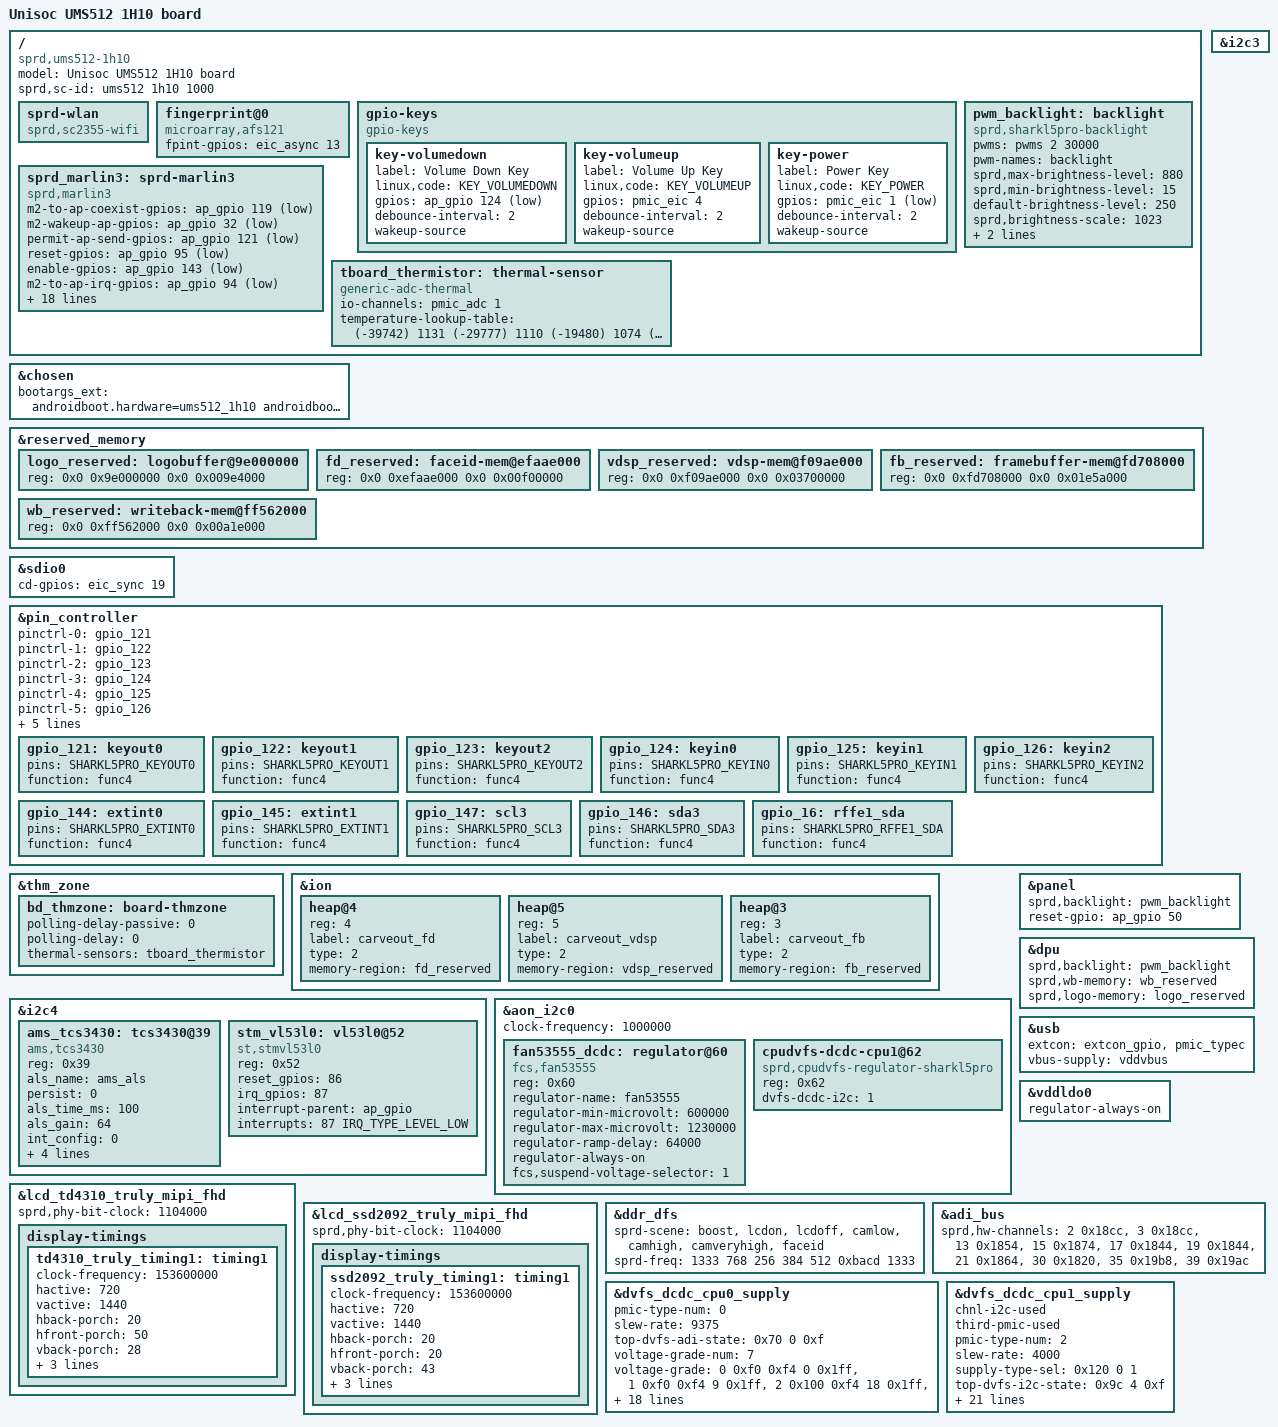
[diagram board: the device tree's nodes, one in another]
/dts-v1/;
/plugin/;

#include <dt-bindings/input/input.h>
#include <dt-bindings/gpio/gpio.h>
#include <dt-bindings/interrupt-controller/arm-gic.h>
#include <dt-bindings/clock/sprd,sharkl5pro-clk.h>
#include <dt-bindings/mfd/sprd,sc2730-regs.h>
#include <dt-bindings/mfd/sprd,sc2730-mask.h>
#include "../lcd/lcd_td4310_truly_mipi_fhd.dtsi"
#include "../lcd/lcd_ssd2092_truly_mipi_fhd.dtsi"
#include "../lcd/lcd_dummy_mipi.dtsi"

/ {

	model = "Unisoc UMS512 1H10 board";
	compatible = "sprd,ums512-1h10";
	sprd,sc-id = "ums512 1h10 1000";

	fragment {
		target-path = "/";
		__overlay__ {
			sprd-wlan {
				compatible = "sprd,sc2355-wifi";
			};

			fingerprint@0 {
				compatible = "microarray,afs121";
				fpint-gpios = <&eic_async 13 0>;
			};

			gpio-keys {
				compatible = "gpio-keys";

				key-volumedown {
					label = "Volume Down Key";
					linux,code = <KEY_VOLUMEDOWN>;
					gpios = <&ap_gpio 124 GPIO_ACTIVE_LOW>;
					debounce-interval = <2>;
					wakeup-source;
				};

				key-volumeup {
					label = "Volume Up Key";
					linux,code = <KEY_VOLUMEUP>;
					gpios = <&pmic_eic 4 GPIO_ACTIVE_HIGH>;
					debounce-interval = <2>;
					wakeup-source;
				};

				key-power {
					label = "Power Key";
					linux,code = <KEY_POWER>;
					gpios = <&pmic_eic 1 GPIO_ACTIVE_LOW>;
					debounce-interval = <2>;
					wakeup-source;
				};
			};

			pwm_backlight: backlight {
				compatible = "sprd,sharkl5pro-backlight";
				pwms = <&pwms 2 30000>;
				pwm-names = "backlight";
				sprd,max-brightness-level = <880>;
				sprd,min-brightness-level = <15>;
				default-brightness-level = <250>;
				sprd,brightness-scale = <1023>;
				brightness-levels = <
							  0   3   4   5   6   7
					  8   9  10  11  12  13  14  15  16  17
					 18  19  20  21  22  23  24  25  26  27
					 28  29  31  33  35  37  39  41  43  45
					 46  48  50  52  54  56  58  60  62  64
					 66  68  70  72  74  76  78  80  82  84
					 86  88  90  92  94  96  98 100 102 104
					106 108 110 112 114 116 118 120 122 124
					126 128 130 132 134 136 138 140 142 144
					146 148 150 152 154 156 158 160 162 164
					166 169 172 175 178 181 184 187 190 193
					196 199 202 205 208 211 214 217 220 223
					226 229 232 235 238 241 244 247 250 253
					256 259 262 265 268 271 274 277 280 283
					286 290 294 298 302 306 310 314 318 322
					326 330 334 338 342 346 350 354 358 362
					366 370 374 378 382 386 390 394 398 402
					406 410 414 418 422 426 430 434 438 442
					446 451 456 461 466 471 476 481 486 491
					496 501 506 511 516 521 526 531 536 541
					546 551 556 561 566 571 576 581 586 591
					596 601 606 611 616 621 626 631 636 641
					646 652 658 664 670 676 682 688 694 700
					706 712 718 724 730 736 742 748 754 760
					766 772 778 784 790 796 802 808 814 820
					826 832 838 844 850 856 862 868 874 880
				>;
			};

			sprd_marlin3: sprd-marlin3 {
				compatible = "sprd,marlin3";
				m2-to-ap-coexist-gpios = <&ap_gpio 119 GPIO_ACTIVE_LOW>;
				m2-wakeup-ap-gpios = <&ap_gpio 32 GPIO_ACTIVE_LOW>;
				permit-ap-send-gpios = <&ap_gpio 121 GPIO_ACTIVE_LOW>;
				reset-gpios = <&ap_gpio 95 GPIO_ACTIVE_LOW>;
				enable-gpios = <&ap_gpio 143 GPIO_ACTIVE_LOW>;
				m2-to-ap-irq-gpios = <&ap_gpio 94 GPIO_ACTIVE_LOW>;
				avdd12-supply = <&vddwcn>;
				avdd33-supply = <&vddwifipa>;
				dcxo18-supply = <&vddsim2>;

				clock-names = "clk_32k","source","enable";
				clocks = <&aon_clk CLK_AUX0>,
					 <&ext_32k>,
					 <&aonapb_gate CLK_AUX0_EB>;

				sdhci-name = <&sdio1>;
				sprd,btwf-file-name =
					"/dev/block/platform/soc/soc:ap-apb/71400000.sdio/by-name/wcnmodem";
				sprd,gnss-file-name =
					"/dev/block/platform/soc/soc:ap-apb/71400000.sdio/by-name/gnssmodem";
				adma-tx;
				adma-rx;
				/*
				 * bound parameter:
				 * [0]:addr offset, [1]:mask, [2]:unboundval, [3]:boundval
				 */
				avdd12-parent-bound-chip = <
					REG_ANA_SLP_DCDC_PD_CTRL
					MASK_ANA_SLP_DCDCGEN1_PD_EN 0x0 MASK_ANA_SLP_DCDCGEN1_PD_EN>;
				avdd12-bound-wbreq = <
					REG_ANA_LDO_XTL_EN10
					MASK_ANA_LDO_VDDWCN_EXT_XTL3_EN 0x0 MASK_ANA_LDO_VDDWCN_EXT_XTL3_EN>;
				avdd33-bound-wbreq = <
					REG_ANA_LDO_XTL_EN11
					MASK_ANA_LDO_VDDWIFIPA_EXT_XTL3_EN 0x0 MASK_ANA_LDO_VDDWIFIPA_EXT_XTL3_EN>;
			};

			tboard_thermistor:thermal-sensor {
				compatible = "generic-adc-thermal";
				#thermal-sensor-cells = <0>;
				io-channels = <&pmic_adc 1>;
				io-channel-names = "sensor-channel";
				temperature-lookup-table = <    (-39742) 1131
								(-29777) 1110
								(-19480) 1074
								(-4679) 983
								10110 838
								24805 654
								44922 413
								54903 316
								64895 238
								74884 178
								84883 133
								94883 100
								104880 75
								114889 57
								124872 43 >;
			};
		};
	};
};

&chosen {
	bootargs_ext = "androidboot.hardware=ums512_1h10 androidboot.dtbo_idx=0";
};

&reserved_memory {

	logo_reserved: logobuffer@9e000000{
		reg = <0x0 0x9e000000 0x0 0x009e4000>;
	};

	fd_reserved: faceid-mem@efaae000 {
		reg = <0x0 0xefaae000 0x0 0x00f00000>;
	};

	vdsp_reserved: vdsp-mem@f09ae000 {
		reg = <0x0 0xf09ae000 0x0 0x03700000>;
	};
/*
	gpu_reserved: gpu-mem@fb8ae000 {
		reg = <0x0 0xfb8ae000 0x0 0x01e5a000>;
	};
*/

	fb_reserved: framebuffer-mem@fd708000 {
		reg = <0x0 0xfd708000 0x0 0x01e5a000>;
	};

	wb_reserved: writeback-mem@ff562000 {
		reg = <0x0 0xff562000 0x0 0x00a1e000>;
	};

};

&sdio0 {
	cd-gpios = <&eic_sync 19 GPIO_ACTIVE_HIGH>;
};

&pin_controller {
	pinctrl-names =
	/* keyout0 ~ keyout2 */
	"gpio_121", "gpio_122", "gpio_123",
	/* keyin0 ~ keyin2 */
	"gpio_124", "gpio_125", "gpio_126",
	/* extint0, extint1, scl3, sda3, sda */
	"gpio_144", "gpio_145", "gpio_146", "gpio_147", "gpio_16";

	pinctrl-0 = <&gpio_121>;
	pinctrl-1 = <&gpio_122>;
	pinctrl-2 = <&gpio_123>;
	pinctrl-3 = <&gpio_124>;
	pinctrl-4 = <&gpio_125>;
	pinctrl-5 = <&gpio_126>;
	pinctrl-6 = <&gpio_144>;
	pinctrl-7 = <&gpio_145>;
	pinctrl-8 = <&gpio_146>;
	pinctrl-9 = <&gpio_147>;
	pinctrl-10 = <&gpio_16>;

	gpio_121: keyout0 {
		pins = "SHARKL5PRO_KEYOUT0";
		function = "func4";
	};

	gpio_122: keyout1 {
		pins = "SHARKL5PRO_KEYOUT1";
		function = "func4";
	};

	gpio_123: keyout2 {
		pins = "SHARKL5PRO_KEYOUT2";
		function = "func4";
	};

	gpio_124: keyin0 {
		pins = "SHARKL5PRO_KEYIN0";
		function = "func4";
	};

	gpio_125: keyin1 {
		pins = "SHARKL5PRO_KEYIN1";
		function = "func4";
	};

	gpio_126: keyin2 {
		pins = "SHARKL5PRO_KEYIN2";
		function = "func4";
	};

	gpio_144: extint0 {
		pins = "SHARKL5PRO_EXTINT0";
		function = "func4";
	};

	gpio_145: extint1 {
		pins = "SHARKL5PRO_EXTINT1";
		function = "func4";
	};

	gpio_147: scl3 {
		pins = "SHARKL5PRO_SCL3";
		function = "func4";
	};

	gpio_146: sda3 {
		pins = "SHARKL5PRO_SDA3";
		function = "func4";
	};

	gpio_16: rffe1_sda {
		pins = "SHARKL5PRO_RFFE1_SDA";
		function = "func4";
	};
};

&thm_zone {
	bd_thmzone: board-thmzone {
		polling-delay-passive = <0>;
		polling-delay = <0>;
		thermal-sensors = <&tboard_thermistor>;
	};
};

&ion {
	heap@4 {
		reg = <4>;
		label = "carveout_fd";
		type = <2>;
		memory-region = <&fd_reserved>;
	};

	heap@5 {
		reg = <5>;
		label = "carveout_vdsp";
		type = <2>;
		memory-region = <&vdsp_reserved>;
	};
};

&i2c3 {
	status = "okay";

};

&i2c4 {
	status = "okay";


	ams_tcs3430: tcs3430@39 {
		compatible = "ams,tcs3430";
		reg = <0x39>;
		als_name = "ams_als";
		persist = <0>;
		als_time_ms = <100>;
		als_gain = <64>;
		int_config = <0>;
		als_can_wake = <1>;
		irq_gpios = <112>;
		interrupt-parent = <&ap_gpio>;
		interrupts = <112 IRQ_TYPE_LEVEL_LOW>;
	};

	stm_vl53l0: vl53l0@52 {
		compatible = "st,stmvl53l0";
		reg = <0x52>;
		reset_gpios = <86>;
		irq_gpios = <87>;
		interrupt-parent = <&ap_gpio>;
		interrupts = <87 IRQ_TYPE_LEVEL_LOW>;
	};

};

&aon_i2c0 {
	status = "okay";
	clock-frequency = <1000000>;

	fan53555_dcdc: regulator@60 {
		compatible = "fcs,fan53555";
		reg = <0x60>;
		regulator-name = "fan53555";
		regulator-min-microvolt = <600000>;
		regulator-max-microvolt = <1230000>;
		regulator-ramp-delay = <64000>;
		regulator-always-on;
		fcs,suspend-voltage-selector = <1>;
	};

	/* A virtual i2c device */
	cpudvfs-dcdc-cpu1@62{
		compatible = "sprd,cpudvfs-regulator-sharkl5pro";
		reg = <0x62>;
		dvfs-dcdc-i2c = <1>;
	};
};

&panel {
	sprd,backlight = <&pwm_backlight>;
	reset-gpio = <&ap_gpio 50 GPIO_ACTIVE_HIGH>;
};

&dpu {
	sprd,backlight = <&pwm_backlight>;
};

&lcd_td4310_truly_mipi_fhd {
	sprd,phy-bit-clock = <1104000>;  /* kbps */

	display-timings {
		td4310_truly_timing1: timing1 {
			clock-frequency = <153600000>;
			hactive = <720>;
			vactive = <1440>;
			hback-porch = <20>;
			hfront-porch = <50>;
			vback-porch = <28>;
			vfront-porch = <4>;
			hsync-len = <2>;
			vsync-len = <2>;
		};
	};
};

&lcd_ssd2092_truly_mipi_fhd {
	sprd,phy-bit-clock = <1104000>;  /* kbps */

	display-timings {
		ssd2092_truly_timing1: timing1 {
			clock-frequency = <153600000>;
			hactive = <720>;
			vactive = <1440>;
			hback-porch = <20>;
			hfront-porch = <20>;
			vback-porch = <43>;
			vfront-porch = <76>;
			hsync-len = <4>;
			vsync-len = <1>;
		};
	};
};

&ddr_dfs {
	sprd-scene = "boost", "lcdon", "lcdoff", "camlow",
		"camhigh", "camveryhigh", "faceid";
	sprd-freq = <1333 768 256 384 512 0xbacd 1333>;
};

&usb {
	extcon = <&extcon_gpio>, <&pmic_typec>;
	vbus-supply = <&vddvbus>;
};

&vddldo0 {
	regulator-always-on;
};

&adi_bus {
	sprd,hw-channels = <2 0x18cc>, <3 0x18cc>, <13 0x1854>, <15 0x1874>,
			 <17 0x1844>,<19 0x1844>, <21 0x1864>, <30 0x1820>,
			 <35 0x19b8>, <39 0x19ac>;
};

&dvfs_dcdc_cpu0_supply {
	pmic-type-num = <0>;
	slew-rate = <9375>; /* 9375uV/us */
	top-dvfs-adi-state = <0x70 0 0xf>;
	voltage-grade-num = <7>;
	voltage-grade = <0 0xf0 0xf4 0 0x1ff>,
		<1 0xf0 0xf4 9 0x1ff>,
		<2 0x100 0xf4 18 0x1ff>,
		<3 0x110 0xf8 0 0x1ff>,
		<4 0x120 0xf8 9 0x1ff>,
		<5 0x130 0xf8 18 0x1ff>,
		<6 0x140 0xfc 0 0x1ff>;
	voltage-up-delay = <50 0x58 0 0xffff 0x600>,
		<100 0x58 16 0xffff 0xa00>,
		<150 0x54 0 0xffff 0xf00>,
		<200 0x54 16 0xffff 0x1400>,
		<250 0x50 0 0xffff 0x1900>,
		<300 0x50 16 0xffff 0x1e00>,
		<350 0x110 0 0xffff 0x2300>;
	voltage-down-delay = <50 0x64 0 0xffff 0x600>,
		<100 0x64 16 0xffff 0xa00>,
		<150 0x60 0 0xffff 0xf00>,
		<200 0x60 16 0xffff 0x1400>,
		<250 0x5c 0 0xffff 0x1900>,
		<300 0x5c 16 0xffff 0x1e00>,
		<350 0x114 0 0xffff 0x2300>;
	tuning-latency-us = <0>;
	chnl-in-i2c = <0>;
};

&dvfs_dcdc_cpu1_supply {
	chnl-i2c-used;
	third-pmic-used;
	pmic-type-num = <2>;
	slew-rate = <4000>; /* 4000uV/us */
	supply-type-sel = <0x120 0 1>;
	top-dvfs-i2c-state = <0x9c 4 0xf>;
	voltage-grade-num = <6>;
	voltage-grade = <0 0x0f 0x12c 0 0x7f>,
		<1 0x14 0x12c 7 0x7f>,
		<2 0x19 0x12c 14 0x7f>,
		<3 0x1e 0x12c 21 0x7f>,
		<4 0x23 0x130 0 0x7f>,
		<5 0x28 0x130 7 0x7f>;
	voltage-up-delay = <50 0x84 0 0xffff 0x1600>,
		<100 0x84 16 0xffff 0x1a00>,
		<150 0x80 0 0xffff 0x1f00>,
		<200 0x80 16 0xffff 0x2400>,
		<250 0x7c 0 0xffff 0x2900>,
		<300 0x7c 16 0xffff 0x2e00>,
		<350 0x118 0 0xffff 0x3300>;
	voltage-down-delay = <50 0x90 0 0xffff 0x600>,
		<100 0x90 16 0xffff 0xa00>,
		<150 0x8c 0 0xffff 0xf00>,
		<200 0x8c 16 0xffff 0x1400>,
		<250 0x88 0 0xffff 0x1900>,
		<300 0x88 16 0xffff 0x1e00>,
		<350 0x11c 0 0xffff 0x2300>;
	tuning-latency-us = <0>;
	chnl-in-i2c = <1>;
};

&ion {
	heap@3 {
		reg = <3>;
		label = "carveout_fb";
		type = <2>;
		memory-region = <&fb_reserved>;
	};
};

&dpu {
	sprd,wb-memory = <&wb_reserved>;
	sprd,logo-memory = <&logo_reserved>;
};
